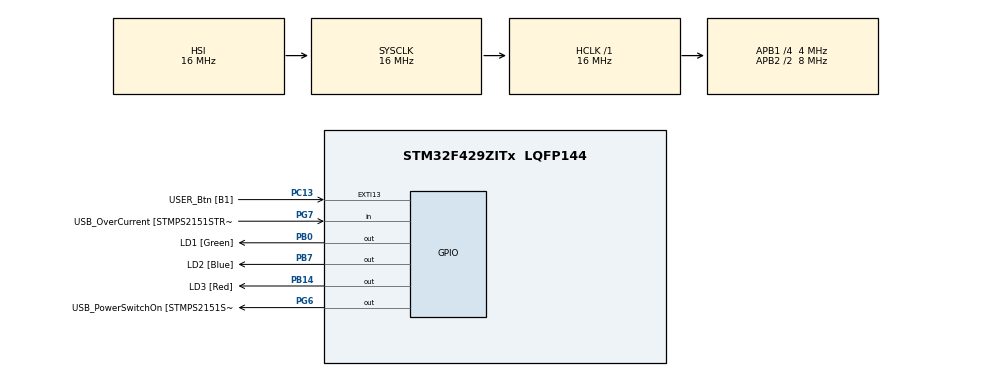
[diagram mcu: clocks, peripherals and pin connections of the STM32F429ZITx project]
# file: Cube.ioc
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Mcu.Family=STM32F4
RCC.CortexFreq_Value=16000000
PG6.Signal=GPIO_Output
PG7.Signal=GPIO_Input
PC13.Signal=GPXTI13
PB14.GPIO_Label=LD3 [Red]
PG6.GPIO_Label=USB_PowerSwitchOn [STMPS2151STR_EN]
PA14.GPIO_Label=TCK
RCC.SYSCLKSourceVirtual=RCC_SYSCLKSOURCE_PLLCLK
PB0.GPIO_Label=LD1 [Green]
PC13.GPIO_Label=USER_Btn [B1]
RCC.APB1CLKDivider=RCC_HCLK_DIV4
ProjectManager.StackSize=0x400
PA13.Signal=SYS_JTMS-SWDIO
ProjectManager.TargetToolchain=Makefile
RCC.HCLKFreq_Value=16000000
RCC.APB2TimFreq_Value=16000000
RCC.USBFreq_Value=48000000
RCC.AHBFreq_Value=16000000
NVIC.EXTI15_10_IRQn=true\:5\:0\:true\:false\:true\:true\:true
PB14.Signal=GPIO_Output
RCC.HSE_VALUE=8000000
board=NUCLEO-F429ZI
RCC.VCOOutputFreq_Value=672000000
RCC.PLLMUL=RCC_PLL_MUL9
RCC.APB2Freq_Value=8000000
RCC.PRESCALERUSB=RCC_USBCLKSOURCE_PLL_DIV1_5
PA14.Mode=Serial_Wire
PG7.GPIO_Label=USB_OverCurrent [STMPS2151STR_FAULT]
PB7.Signal=GPIO_Output
PA13.Mode=Serial_Wire
Mcu.Name=STM32F429ZITx
PA13.GPIO_Label=TMS
RCC.APB2TimCLKDivider=2
PB7.GPIO_Label=LD2 [Blue]
RCC.48MHZClocksFreq_Value=96000000
RCC.SYSCLKFreq_VALUE=16000000
Mcu.Package=LQFP144
PA14.Signal=SYS_JTCK-SWCLK
ProjectManager.HeapSize=0x200
RCC.HSI_VALUE=16000000
RCC.PLLQ=7
NVIC.PriorityGroup=NVIC_PRIORITYGROUP_4
RCC.APB2CLKDivider=RCC_HCLK_DIV2
RCC.PLLM=4
RCC.PLLN=168
RCC.APB1TimFreq_Value=8000000
RCC.APB1Freq_Value=4000000
PB0.Signal=GPIO_Output

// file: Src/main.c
/* USER CODE BEGIN Header */
/**
  ******************************************************************************
  * @file           : main.c
  * @brief          : Main program body
  ******************************************************************************
  * @attention
  *
  * <h2><center>&copy; Copyright (c) 2020 STMicroelectronics.
  * All rights reserved.</center></h2>
  *
  * This software component is licensed by ST under BSD 3-Clause license,
  * the "License"; You may not use this file except in compliance with the
  * License. You may obtain a copy of the License at:
  *                        opensource.org/licenses/BSD-3-Clause
  *
  ******************************************************************************
  */
/* USER CODE END Header */
#include "main.h"
#include "gpio.h"

/* USER CODE BEGIN Includes */
#include "stm32f4xx_it.h"
/* USER CODE END Includes */

//void SystemClock_Config(void);

void SystemClock_Config(void)
{
  RCC_OscInitTypeDef RCC_OscInitStruct = {0};
  RCC_ClkInitTypeDef RCC_ClkInitStruct = {0};

  /** Configure the main internal regulator output voltage
  */
  __HAL_RCC_PWR_CLK_ENABLE();
  __HAL_PWR_VOLTAGESCALING_CONFIG(PWR_REGULATOR_VOLTAGE_SCALE3);
  /** Initializes the RCC Oscillators according to the specified parameters
  * in the RCC_OscInitTypeDef structure.
  */
  RCC_OscInitStruct.OscillatorType = RCC_OSCILLATORTYPE_HSI;
  RCC_OscInitStruct.HSIState = RCC_HSI_ON;
  RCC_OscInitStruct.HSICalibrationValue = RCC_HSICALIBRATION_DEFAULT;
  RCC_OscInitStruct.PLL.PLLState = RCC_PLL_NONE;
  if (HAL_RCC_OscConfig(&RCC_OscInitStruct) != HAL_OK)
  {
    Error_Handler();
  }
  /** Initializes the CPU, AHB and APB buses clocks
  */
  RCC_ClkInitStruct.ClockType = RCC_CLOCKTYPE_HCLK|RCC_CLOCKTYPE_SYSCLK
                              |RCC_CLOCKTYPE_PCLK1|RCC_CLOCKTYPE_PCLK2;
  RCC_ClkInitStruct.SYSCLKSource = RCC_SYSCLKSOURCE_HSI;
  RCC_ClkInitStruct.AHBCLKDivider = RCC_SYSCLK_DIV1;
  RCC_ClkInitStruct.APB1CLKDivider = RCC_HCLK_DIV4;
  RCC_ClkInitStruct.APB2CLKDivider = RCC_HCLK_DIV2;

  if (HAL_RCC_ClockConfig(&RCC_ClkInitStruct, FLASH_LATENCY_0) != HAL_OK)
  {
    Error_Handler();
  }
}

void Error_Handler(void)
{
  __disable_irq();
  while (1)
  {
  }
}

/************************ (C) COPYRIGHT STMicroelectronics *****END OF FILE****/
